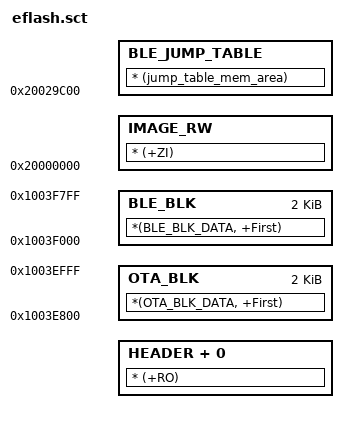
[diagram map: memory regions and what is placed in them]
; *************************************************************
; *** Scatter-Loading Description File generated by uVision ***
; *************************************************************

SOC 0x10000000 0x40000  ; 256KB
{
    STARTUP + 0 
    {
        *(VECTOR_TABLE, +First)
    }

    HEADER + 0 FIXED                ;should always start from offset 0xC0
    {
        *(IMAGE_HEADER, +First)
        *(InRoot$$Sections)
    }

    IMAGE_RO + 0
    {        
        * (+RO)
    }

    IMAGE_RW 0x20000000      ; fixed address after BootROM BLE_ZI
    {
        *(RO_IN_SYS_RAM)
        
        * (+RW)
    }

    IMAGE_ZI + 0
    {
        
        * (+ZI)
    }

    BLE_JUMP_TABLE 0x20029C00 
    {
        * (jump_table_mem_area)
    }
    
    OTA_BLK 0x1003E800 PADVALUE 0xFFFFFFFF 0x800
    {
        *(OTA_BLK_DATA, +First)
    }
    BLE_BLK 0x1003F000 PADVALUE 0xFFFFFFFF 0x800
    {
        *(BLE_BLK_DATA, +First)
    }
    ;PROTECT_BLK 0x1003F800 PADVALUE 0xFFFFFFFF 0x800
    ;{
    ;}    

}


